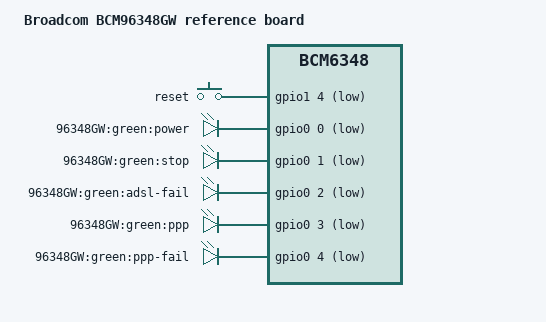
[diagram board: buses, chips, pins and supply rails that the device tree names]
/dts-v1/;

#include "bcm6348.dtsi"

#include <dt-bindings/input/input.h>

/ {
	model = "Broadcom BCM96348GW reference board";
	compatible = "brcm,bcm96348gw", "brcm,bcm6348";

	chosen {
		bootargs = "root=/dev/mtdblock2 rootfstype=squashfs,jffs2 noinitrd console=ttyS0,115200";
	};

	gpio-keys-polled {
		compatible = "gpio-keys-polled";
		#address-cells = <1>;
		#size-cells = <0>;
		poll-interval = <20>;
		debounce-interval = <60>;

		reset {
			label = "reset";
			gpios = <&gpio1 4 1>;
			linux,code = <KEY_RESTART>;
		};
	};

	gpio-leds {
		compatible = "gpio-leds";

		power_green {
			label = "96348GW:green:power";
			gpios = <&gpio0 0 1>;
			default-state = "on";
		};
		stop_green {
			label = "96348GW:green:stop";
			gpios = <&gpio0 1 1>;
		};
		adsl_fail_green {
			label = "96348GW:green:adsl-fail";
			gpios = <&gpio0 2 1>;
		};
		ppp_green {
			label = "96348GW:green:ppp";
			gpios = <&gpio0 3 1>;
		};
		ppp_fail_green {
			label = "96348GW:green:ppp-fail";
			gpios = <&gpio0 4 1>;
		};
	};
};
